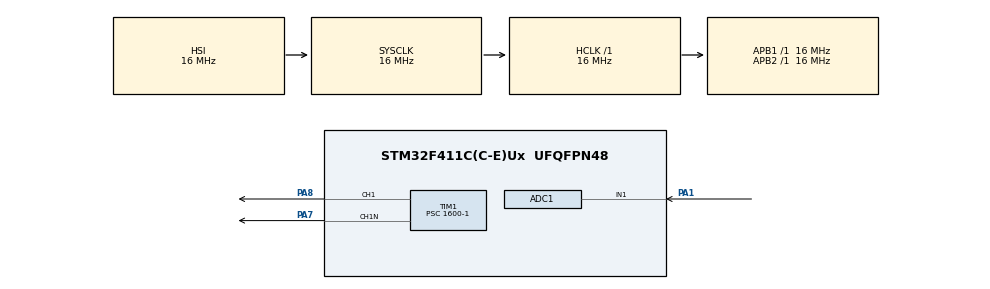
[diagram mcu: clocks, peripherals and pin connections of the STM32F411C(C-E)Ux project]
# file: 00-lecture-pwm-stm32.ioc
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ADC1.Channel-1\#ChannelRegularConversion=ADC_CHANNEL_1
ADC1.ContinuousConvMode=ENABLE
ADC1.NbrOfConversionFlag=1
ADC1.Rank-1\#ChannelRegularConversion=1
ADC1.SamplingTime-1\#ChannelRegularConversion=ADC_SAMPLETIME_480CYCLES
ADC1.master=1
Mcu.Family=STM32F4
Mcu.Name=STM32F411C(C-E)Ux
Mcu.Package=UFQFPN48
NVIC.ADC_IRQn=true\:0\:0\:false\:false\:true\:true\:true\:true
NVIC.PriorityGroup=NVIC_PRIORITYGROUP_4
PA1.Signal=ADCx_IN1
PA7.Mode=PWM Generation1 CH1 CH1N
PA7.Signal=TIM1_CH1N
PA8.Signal=S_TIM1_CH1
ProjectManager.HeapSize=0x200
ProjectManager.StackSize=0x400
ProjectManager.TargetToolchain=STM32CubeIDE
RCC.AHBFreq_Value=16000000
RCC.APB1Freq_Value=16000000
RCC.APB2Freq_Value=16000000
RCC.CortexFreq_Value=16000000
RCC.HSE_VALUE=25000000
RCC.HSI_VALUE=16000000
RCC.LSE_VALUE=32768
RCC.SYSCLKFreq_VALUE=16000000
RCC.VCOOutputFreq_Value=192000000
SH.ADCx_IN1.0=ADC1_IN1,IN1
SH.S_TIM1_CH1.0=TIM1_CH1,PWM Generation1 CH1 CH1N
TIM1.Channel-PWM\ Generation1\ CH1\ CH1N=TIM_CHANNEL_1
TIM1.Period=1000-1
TIM1.Prescaler=1600-1
board=custom

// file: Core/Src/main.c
/* USER CODE BEGIN Header */
/**
  ******************************************************************************
  * @file           : main.c
  * @brief          : Main program body
  ******************************************************************************
  * @attention
  *
  * Copyright (c) 2026 STMicroelectronics.
  * All rights reserved.
  *
  * This software is licensed under terms that can be found in the LICENSE file
  * in the root directory of this software component.
  * If no LICENSE file comes with this software, it is provided AS-IS.
  *
  ******************************************************************************
  */
/* USER CODE END Header */
#include "main.h"

ADC_HandleTypeDef hadc1;

TIM_HandleTypeDef htim1;

/* USER CODE BEGIN PV */
volatile uint16_t adc_value = 0u;  // the last ADC result, written by the ADC interrupt
volatile uint8_t adc_ready = 0u;   // 1 = a new result is waiting for main
/* USER CODE END PV */

void SystemClock_Config(void);
static void MX_GPIO_Init(void);
static void MX_TIM1_Init(void);
static void MX_ADC1_Init(void);

int main(void)
{

  /* MCU Configuration--------------------------------------------------------*/

  /* Reset of all peripherals, Initializes the Flash interface and the Systick. */
  HAL_Init();

  /* Configure the system clock */
  SystemClock_Config();

  /* Initialize all configured peripherals */
  MX_GPIO_Init();
  MX_TIM1_Init();
  MX_ADC1_Init();
  /* USER CODE BEGIN 2 */
  HAL_TIM_PWM_Start(&htim1, TIM_CHANNEL_1);           // CH1 on PA8
  HAL_TIMEx_PWMN_Start(&htim1, TIM_CHANNEL_1);        // CH1N on PA7: the complementary (inverted) output
  __HAL_TIM_SET_COMPARE(&htim1, TIM_CHANNEL_1, 250);  // CCR1 = 250 of ARR + 1 = 1000: 25 % until the first ADC result
  HAL_ADC_Start_IT(&hadc1);  // ADC on with the end-of-conversion interrupt; continuous mode: it keeps converting
  /* USER CODE END 2 */

  /* Infinite loop */
  /* USER CODE BEGIN WHILE */
  uint16_t adc_corrected = 0;
  while (1)
  {
    if (adc_ready == 1u)  // the ADC interrupt left a new result
    {
      // the potentiometer 0..4000 -> CCR 0..1000 = 0..100 % duty (ARR + 1 = 1000)
      adc_corrected = (adc_value > 4000u) ? 1000u : (uint16_t)(adc_value / 4u);
      __HAL_TIM_SET_COMPARE(&htim1, TIM_CHANNEL_1, adc_corrected);
      adc_ready = 0u;  // result taken
    }
    /* USER CODE END WHILE */

  }
}

void SystemClock_Config(void)
{
  RCC_OscInitTypeDef RCC_OscInitStruct = {0};
  RCC_ClkInitTypeDef RCC_ClkInitStruct = {0};

  /** Configure the main internal regulator output voltage
  */
  __HAL_RCC_PWR_CLK_ENABLE();
  __HAL_PWR_VOLTAGESCALING_CONFIG(PWR_REGULATOR_VOLTAGE_SCALE1);

  /** Initializes the RCC Oscillators according to the specified parameters
  * in the RCC_OscInitTypeDef structure.
  */
  RCC_OscInitStruct.OscillatorType = RCC_OSCILLATORTYPE_HSI;
  RCC_OscInitStruct.HSIState = RCC_HSI_ON;
  RCC_OscInitStruct.HSICalibrationValue = RCC_HSICALIBRATION_DEFAULT;
  RCC_OscInitStruct.PLL.PLLState = RCC_PLL_NONE;
  if (HAL_RCC_OscConfig(&RCC_OscInitStruct) != HAL_OK)
  {
    Error_Handler();
  }

  /** Initializes the CPU, AHB and APB buses clocks
  */
  RCC_ClkInitStruct.ClockType = RCC_CLOCKTYPE_HCLK|RCC_CLOCKTYPE_SYSCLK
                              |RCC_CLOCKTYPE_PCLK1|RCC_CLOCKTYPE_PCLK2;
  RCC_ClkInitStruct.SYSCLKSource = RCC_SYSCLKSOURCE_HSI;
  RCC_ClkInitStruct.AHBCLKDivider = RCC_SYSCLK_DIV1;
  RCC_ClkInitStruct.APB1CLKDivider = RCC_HCLK_DIV1;
  RCC_ClkInitStruct.APB2CLKDivider = RCC_HCLK_DIV1;

  if (HAL_RCC_ClockConfig(&RCC_ClkInitStruct, FLASH_LATENCY_0) != HAL_OK)
  {
    Error_Handler();
  }
}

static void MX_ADC1_Init(void)
{

  ADC_ChannelConfTypeDef sConfig = {0};

  /** Configure the global features of the ADC (Clock, Resolution, Data Alignment and number of conversion)
  */
  hadc1.Instance = ADC1;
  hadc1.Init.ClockPrescaler = ADC_CLOCK_SYNC_PCLK_DIV2;
  hadc1.Init.Resolution = ADC_RESOLUTION_12B;
  hadc1.Init.ScanConvMode = DISABLE;
  hadc1.Init.ContinuousConvMode = ENABLE;
  hadc1.Init.DiscontinuousConvMode = DISABLE;
  hadc1.Init.ExternalTrigConvEdge = ADC_EXTERNALTRIGCONVEDGE_NONE;
  hadc1.Init.ExternalTrigConv = ADC_SOFTWARE_START;
  hadc1.Init.DataAlign = ADC_DATAALIGN_RIGHT;
  hadc1.Init.NbrOfConversion = 1;
  hadc1.Init.DMAContinuousRequests = DISABLE;
  hadc1.Init.EOCSelection = ADC_EOC_SINGLE_CONV;
  if (HAL_ADC_Init(&hadc1) != HAL_OK)
  {
    Error_Handler();
  }

  /** Configure for the selected ADC regular channel its corresponding rank in the sequencer and its sample time.
  */
  sConfig.Channel = ADC_CHANNEL_1;
  sConfig.Rank = 1;
  sConfig.SamplingTime = ADC_SAMPLETIME_480CYCLES;
  if (HAL_ADC_ConfigChannel(&hadc1, &sConfig) != HAL_OK)
  {
    Error_Handler();
  }

}

static void MX_TIM1_Init(void)
{

  TIM_MasterConfigTypeDef sMasterConfig = {0};
  TIM_OC_InitTypeDef sConfigOC = {0};
  TIM_BreakDeadTimeConfigTypeDef sBreakDeadTimeConfig = {0};

  htim1.Instance = TIM1;
  htim1.Init.Prescaler = 1600-1;
  htim1.Init.CounterMode = TIM_COUNTERMODE_UP;
  htim1.Init.Period = 1000-1;
  htim1.Init.ClockDivision = TIM_CLOCKDIVISION_DIV1;
  htim1.Init.RepetitionCounter = 0;
  htim1.Init.AutoReloadPreload = TIM_AUTORELOAD_PRELOAD_DISABLE;
  if (HAL_TIM_PWM_Init(&htim1) != HAL_OK)
  {
    Error_Handler();
  }
  sMasterConfig.MasterOutputTrigger = TIM_TRGO_RESET;
  sMasterConfig.MasterSlaveMode = TIM_MASTERSLAVEMODE_DISABLE;
  if (HAL_TIMEx_MasterConfigSynchronization(&htim1, &sMasterConfig) != HAL_OK)
  {
    Error_Handler();
  }
  sConfigOC.OCMode = TIM_OCMODE_PWM1;
  sConfigOC.Pulse = 0;
  sConfigOC.OCPolarity = TIM_OCPOLARITY_HIGH;
  sConfigOC.OCNPolarity = TIM_OCNPOLARITY_HIGH;
  sConfigOC.OCFastMode = TIM_OCFAST_DISABLE;
  sConfigOC.OCIdleState = TIM_OCIDLESTATE_RESET;
  sConfigOC.OCNIdleState = TIM_OCNIDLESTATE_RESET;
  if (HAL_TIM_PWM_ConfigChannel(&htim1, &sConfigOC, TIM_CHANNEL_1) != HAL_OK)
  {
    Error_Handler();
  }
  sBreakDeadTimeConfig.OffStateRunMode = TIM_OSSR_DISABLE;
  sBreakDeadTimeConfig.OffStateIDLEMode = TIM_OSSI_DISABLE;
  sBreakDeadTimeConfig.LockLevel = TIM_LOCKLEVEL_OFF;
  sBreakDeadTimeConfig.DeadTime = 0;
  sBreakDeadTimeConfig.BreakState = TIM_BREAK_DISABLE;
  sBreakDeadTimeConfig.BreakPolarity = TIM_BREAKPOLARITY_HIGH;
  sBreakDeadTimeConfig.AutomaticOutput = TIM_AUTOMATICOUTPUT_DISABLE;
  if (HAL_TIMEx_ConfigBreakDeadTime(&htim1, &sBreakDeadTimeConfig) != HAL_OK)
  {
    Error_Handler();
  }
  HAL_TIM_MspPostInit(&htim1);

}

static void MX_GPIO_Init(void)
{

  /* GPIO Ports Clock Enable */
  __HAL_RCC_GPIOA_CLK_ENABLE();

}

/* USER CODE BEGIN 4 */
void HAL_ADC_ConvCpltCallback(ADC_HandleTypeDef *hadc)
{
    if (hadc == &hadc1)  // only ADC1 here; the check matters once a project has more ADCs
    {
        adc_value = hadc1.Instance->DR;  // read the data register directly (what HAL_ADC_GetValue does)
        adc_ready = 1;

    }
}
/* USER CODE END 4 */

void Error_Handler(void)
{
  __disable_irq();
  while (1)
  {
  }
}
